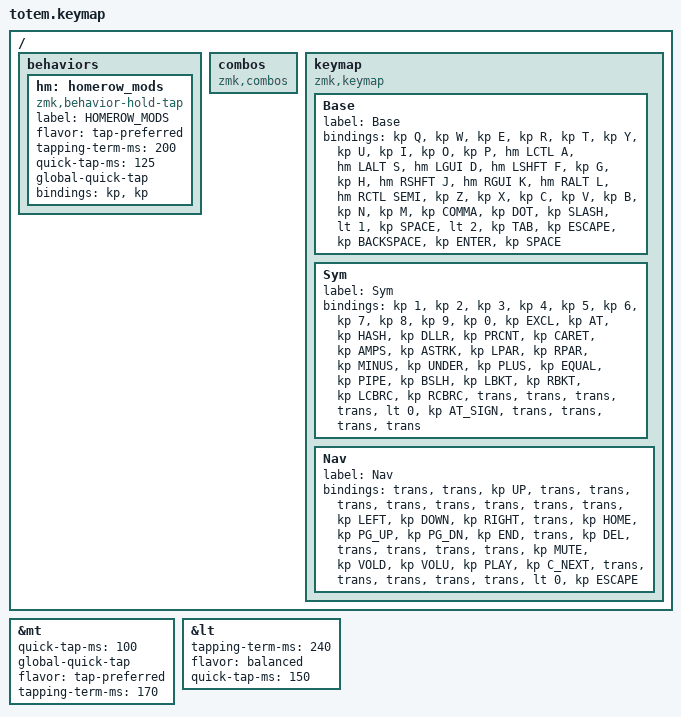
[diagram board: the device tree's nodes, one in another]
#include <behaviors.dtsi>
#include <dt-bindings/zmk/bt.h>
#include <dt-bindings/zmk/ext_power.h>
#include <dt-bindings/zmk/keys.h>

#define Base        0
#define Sym         1  // ✅ Moved Sym to layer 1
#define Nav         2
#define Media       3
#define Mouse       4
#define Num         5
#define Fun         6
#define Button      7
#define Game        8
#define Gameplus    9

&mt {
    quick-tap-ms = <100>;
    global-quick-tap;
    flavor = "tap-preferred";
    tapping-term-ms = <170>;
};

&lt {
    tapping-term-ms = <240>;
    flavor = "balanced";
    quick-tap-ms = <150>;
};

 / {
    behaviors {
        hm: homerow_mods {
            compatible = "zmk,behavior-hold-tap";
            label = "HOMEROW_MODS";
            #binding-cells = <2>;
            flavor = "tap-preferred";
            tapping-term-ms = <200>;
            quick-tap-ms = <125>;
            global-quick-tap;
            bindings = <&kp>, <&kp>;
        };
    };

    combos { compatible = "zmk,combos"; };

    keymap {
        compatible = "zmk,keymap";

        Base {
            label = "Base";
            bindings = <
                &kp Q     &kp W      &kp E          &kp R      &kp T        &kp Y       &kp U         &kp I          &kp O      &kp P
                &hm LCTL A  &hm LALT S  &hm LGUI D  &hm LSHFT F  &kp G        &kp H       &hm RSHFT J   &hm RGUI K     &hm RALT L &hm RCTL SEMI
                &kp Z     &kp X      &kp C          &kp V      &kp B        &kp N       &kp M         &kp COMMA     &kp DOT   &kp SLASH
                &lt 1 &kp SPACE &lt 2 &kp TAB   &kp ESCAPE     &kp BACKSPACE &kp ENTER  &kp SPACE
            >;
        };

        Sym {
            label = "Sym";
            bindings = <
                &kp 1     &kp 2     &kp 3     &kp 4     &kp 5       &kp 6     &kp 7     &kp 8     &kp 9     &kp 0
                &kp EXCL  &kp AT    &kp HASH  &kp DLLR  &kp PRCNT    &kp CARET &kp AMPS  &kp ASTRK &kp LPAR  &kp RPAR
                &kp MINUS &kp UNDER &kp PLUS  &kp EQUAL &kp PIPE     &kp BSLH  &kp LBKT  &kp RBKT  &kp LCBRC &kp RCBRC
                &trans    &trans    &trans    &trans    &lt 0 &kp AT_SIGN &trans &trans &trans &trans  // ✅ Fixed key count
            >;
        };

        Nav {
            label = "Nav";
            bindings = <
                &trans    &trans   &kp UP      &trans   &trans     &trans     &trans     &trans    &trans   &trans
                &trans    &kp LEFT &kp DOWN    &kp RIGHT &trans    &kp HOME   &kp PG_UP  &kp PG_DN &kp END  &trans
                &kp DEL   &trans   &trans      &trans   &trans     &kp MUTE   &kp VOLD   &kp VOLU  &kp PLAY &kp C_NEXT
                &trans    &trans   &trans      &trans   &trans     &lt 0 &kp ESCAPE
            >;
        };
    };
};
